# STM32MP25_CM33 register map
File version: 1.3
CPU: CM33 r0p1, little endian, MPU, FPU, vendor SysTick, 8 interrupt priority bits
Registers are 32-bit, read-write, reset 0x0 unless marked. A register's access mark holds for its fields unless they carry their own. Offsets are from the block's base; [hi:lo] are bit positions; {n}, {i} and the like mark numbered series; 'fields as' and 'values as' point back to an identical list.

## HASH — HASH register bank
Base 0x42010000
Same registers: HASH_S 0x52010000
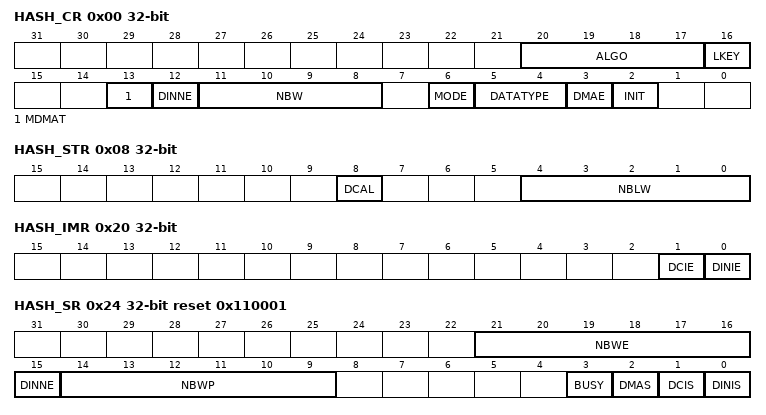
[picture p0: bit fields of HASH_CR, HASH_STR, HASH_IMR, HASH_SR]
0x00 HASH_CR — HASH control register
  [20:17] ALGO — Algorithm selection These bits select the hash algorithm: Others: reserved, must not be used This selection is only taken into account when the INIT bit is set. Changing this bit field during a computation has no effect. When the ALGO bit field is equal to 10XX, an advanced application can use HASH_SHA3CFGR to tune the behavior of the hash processor. When the ALGO bit field is updated and INIT bit is set, NBWE in HASH_SR is automatically updated to 0x11 when ALGO=0x00XX.
    0=SHA-1; 2=SHA2-224; 3=SHA2-256; 12=SHA2-384; 13=SHA2-512/224; 14=SHA2-512/256; 15=SHA2-512; 4=SHA3-224; 5=SHA3-256; 6=SHA3-384; 7=SHA3-512; 8=SHAKE128; 9=SHAKE256
  [16] LKEY — Long key selection The application must set this bit if the HMAC key is greater than the block size corresponding to the hash algorithm (see Table558: Information on supported hash algorithms for details). For example the block size is 64 bytes for SHA2-256. This selection is only taken into account when the INIT and MODE bits are set (HMAC mode selected). Changing this bit during a computation has no effect.
    0=HMAC key is shorter or equal to the block size (short key). The actual key value written in HASH_DIN is used during the HMAC computation.; 1=HMAC key is longer than the block size (long key). The hash of the key is used instead of the real key during the HMAC computation.
  [13] MDMAT — Multiple DMA transfers This bit is set when hashing large files when multiple DMA transfers are needed.
    0=DCAL is automatically set at the end of a DMA transfer; 1=DCAL is not automatically set at the end of a DMA transfer
  [12] DINNE ro — DIN not empty Refer to DINNE bit of HASH_SR for a description of DINNE bit. This bit is read-only.
  [11:8] NBW ro — Number of words already pushed Refer to NBWP[3:0] bit field of HASH_SR for a description of NBW[3:0] bit field. This bit is read-only.
  [6] MODE — Mode selection This bit selects the normal or the keyed HMAC mode for the selected algorithm: This selection is only taken into account when the INIT bit is set. Changing this bit during a computation has no effect.
    0=Hash mode selected; 1=HMAC mode selected. LKEY bit must be set if the key being used is longer than the algorithm block size.
  [5:4] DATATYPE — Data type selection This bit field defines the format of the data entered into the HASH_DIN register:
    0=32-bit data. The data written into HASH_DIN are directly used by the HASH processing, without reordering.; 1=16-bit data or half-word. The data written into HASH_DIN are considered as two half-words, and are swapped before being used by the HASH processing.; 2=8-bit data or bytes. The data written into HASH_DIN are considered as four bytes, and are swapped before being used by the HASH processing.; 3=bit data or bit string. The data written into HASH_DIN are considered as 32 bits (1st bit of the string at position 0), and are swapped before being used by the HASH processing (1st bit of the string at position 31).
  [3] DMAE — DMA enable After this bit is set, it is cleared by hardware while the last data of the message is written into the hash processor. Clearing this bit while a DMA transfer is ongoing does not abort the current transfer. Instead, the DMA interface of the HASH remains internally enabled until the transfer is complete or INIT is set. Setting INIT bit does not clear DMAE bit.
    0=DMA transfers disabled; 1=DMA transfers enabled. A DMA request is sent as soon as the hash core is ready to receive data.
  [2] INIT — Initialize message digest calculation Setting this bit resets the hash processor core, so that the HASH is ready to compute the message digest of a new message. Clearing this bit has no effect. Reading this bit always returns 0.
0x04 HASH_DIN wo — HASH data input register
  [31:0] DATAIN — Data input Writing this register pushes the current register content into the FIFO, and the register takes the new value presented on the AHB bus. Reading this register returns zeros.
0x08 HASH_STR — HASH start register
  [8] DCAL — Digest calculation Setting this bit starts the message padding using the previously written value of NBLW, and starts the calculation of the final message digest with all the data words written to the input FIFO since the INIT bit was last set. Reading this bit returns 0.
  [4:0] NBLW — Number of valid bits in the last word When the last word of the message bit string is written to HASH_DIN register, the hash processor takes only the valid bits, specified as below, after internal data swapping: ... Note: When SHA-3 is selected, bits 0 to 2 are kept at zero (byte oriented input). The above mechanism is valid only if DCAL=0. If NBLW bits are written while DCAL is set , the NBLW bit field remains unchanged. In other words it is not possible to configure NBLW and set DCAL at the same time. Reading NBLW bits returns the last value written to NBLW.
    0=All the 32 bits of the last data written are valid message bits, that is M[31:0]; 1=Only one bit of the last data written (after swapping) is valid, that is M[0]; 2=Only two bits of the last data written (after swapping) are valid, that is M[1:0]; 3=Only three bits of the last data written (after swapping) are valid that is M[2:0]; 31=Only 31 bits of the last data written (after swapping) are valid that is M[30:0]
{0xC+4i} HASH_HRA{i} ro (i=0..4) — HASH aliased digest register {i}
  [31:0] H{i} — Hash data x Refer to Section60.7.4: HASH digest registers introduction.
0x20 HASH_IMR — HASH interrupt enable register
  [1] DCIE — Digest calculation completion interrupt enable
    0=Digest calculation completion interrupt disabled; 1=Digest calculation completion interrupt enabled
  [0] DINIE — Data input interrupt enable
    0=Data input interrupt disabled; 1=Data input interrupt enabled
0x24 HASH_SR reset 0x110001 — HASH status register
  [21:16] NBWE ro — Number of words expected This bit field reflects the number of words in the message that must be pushed into the FIFO to trigger a partial computation. NBWE is decremented by 1 when a write access is performed to the HASH_DIN register. NBWE is set to the expected block size +1 in words when INIT bit is set in HASH_CR. It is set to the expected block size when the partial digest calculation ends.
  [15] DINNE ro — DIN not empty This bit is set when the HASH_DIN register holds valid data (that is after being written at least once). It is cleared when either the INIT bit (initialization) or the DCAL bit (completion of the previous message processing) is set.
    0=No data are present in the data input buffer; 1=The input buffer contains at least one word of data
  [14:9] NBWP ro — Number of words already pushed This bit field is the exact number of words in the message that have already been pushed into the FIFO. NBWP is incremented by 1 when a write access is performed to the HASH_DIN register. When a digest calculation starts, NBWP is updated to NBWP- block size (in words), and NBWP goes to zero when the INIT bit is set.
  [3] BUSY ro — Busy bit
    0=No block is currently being processed; 1=The hash core is processing a block of data
  [2] DMAS ro — DMA Status This bit provides information on the DMA interface activity. It is set with DMAE and cleared when DMAE=0 and no DMA transfer is ongoing. No interrupt is associated with this bit.
    0=DMA interface is disabled (DMAE=0) and no transfer is ongoing; 1=DMA interface is enabled (DMAE=1) or a transfer is ongoing
  [1] DCIS — Digest calculation completion interrupt status This bit is set by hardware when a digest becomes ready (the whole message has been processed). It is cleared by writing it to 0 or by setting the INIT bit in the HASH_CR register.
    0=No digest available in the HASH_HRx registers (zeros are returned); 1=Digest calculation complete, a digest is available in the HASH_HRx registers. An interrupt is generated if the DCIE bit is set in the HASH_IMR register.
  [0] DINIS — Data input interrupt status This bit is set by hardware when the FIFO is ready to get a new block (16 locations are free). It is cleared by writing it to 0 or by writing the HASH_DIN register. When DINIS=0, HASH_CSRx registers reads as zero.
    0=Less than 16 locations are free in the input buffer; 1=A new block can be entered into the input buffer. An interrupt is generated if the DINIE bit is set in the HASH_IMR register.
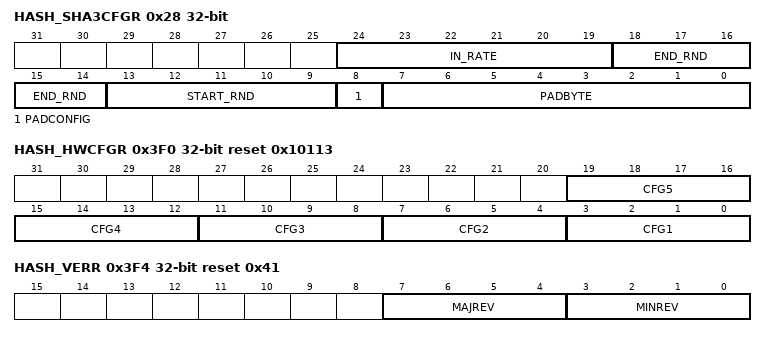
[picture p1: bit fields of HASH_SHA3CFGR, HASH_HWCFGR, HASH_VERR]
0x28 HASH_SHA3CFGR — HASH SHA-3 configuration register
  [24:19] IN_RATE — Input rate This bit field defines the number of 32-bit words corresponding to the input block size. It is also known as input rate. IN_RATE[5:0] must be greater than 0 and lower or equal to 50, else the written value is ignored. Defining the security target of a given sponge function involves defining: the security target against collisions=min (capacity size/2, output_size/2) the security target against preimage attacks=min (capacity size/2, output_size) where capacity size=1600-block_size, in bits. The HASH processor uses the following default input rate values for the algorithm selected through ALGO[3:0] bits: More generally, IN_RATE (in bits)=(1600-capacity) / 32. IN_RATE[5:0] represents the maximum digest output that can be read after each computation, started by setting DCAL bit. Successive settings of DCAL bit are required until the expected digest length is reached (unbounded output used for SHAKE). The number of computations equals the expected output length divided by the block size (IN_RATE[5:0]).
    18=rate=block_size=18*32=576 bits, capacity=1024 bits, default value for SHA3-512; 26=rate=block_size=26*32=832 bits, capacity=768 bits, default value for SHA3-384; 34=rate=block_size=34*32=1088 bits, capacity=512 bits, default value for SHA3-256 or SHAKE256; 36=rate=block_size=36*32=1152 bits, capacity=448 bits, default for SHA3-224; 42=rate=block_size=42*32=1344 bits, capacity=256 bits, default for SHAKE128
  [18:14] END_RND — Last round number This bit field defines the last round of basic block function permutation. The first round starts at START_RND[4:0]. If END_RND[4:0] is programmed to a value greater than 24 or lower than START_RND[4:0], the HASH processor keeps the previous value.
  [13:9] START_RND — Starting round number This bit field defines the first round of basic block function permutation. The last round ends at END_RND[4:0]. If START_RND[4:0] is programmed to a value greater than END_RND[4:0], the HASH processor keeps the previous value.
  [8] PADCONFIG — Padding bit configuration
    0=Padding bit is 0; 1=Padding bit is 1
  [7:0] PADBYTE — Padding byte value This bit field defines the padding byte value to apply.
{0xF8+4i} HASH_CSR{i} (i=0..102) — HASH context swap register {i}
  [31:0] CS{i} — Context swap x Refer to Section60.7.8: HASH context swap registers introduction.
{0x310+4i} HASH_HR{i} ro (i=0..4) — HASH digest register {i}
  fields as HASH_HRA0
{0x310+4i} HASH_HR{i} ro (i=5..49) — HASH supplementary digest register {i}
  fields as HASH_HRA0
0x3F0 HASH_HWCFGR ro reset 0x10113 — HASH hardware configuration register
  [19:16] CFG5 — HW generic 5 This bit field reflects that the SHA384 and SHA512 algorithms are supported.
  [15:12] CFG4 — HW generic 4 This bit field is read as zero.
  [11:8] CFG3 — HW generic 3 This bit field reflects that the SHA3 algorithm is supported.
  [7:4] CFG2 — HW generic 2 This bit field reflects that the HMAC is supported.
  [3:0] CFG1 — HW generic 1 this bit field reflects the DMA type connected to this HASH peripheral.
0x3F4 HASH_VERR ro reset 0x41 — HASH version register
  [7:4] MAJREV — Major revision These bits return the HASH major revision
  [3:0] MINREV — Minor revision These bits return the HASH minor revision
0x3F8 HASH_IPIDR ro reset 0x170031 — HASH identification register
  [31:0] ID — Identifier These bits return the unique identifier of the HASH peripheral.
0x3FC HASH_SIDR ro reset 0xA3C5DD01 — HASH size identification register
  [31:0] SID — Size identification code This bit field returns the size identification code of the HASH peripheral as defined below: Bits[31:8] = 0xA3C5DD (fixed code) Bits[7:0] = 0x01 (1-Kbyte address decoding)
